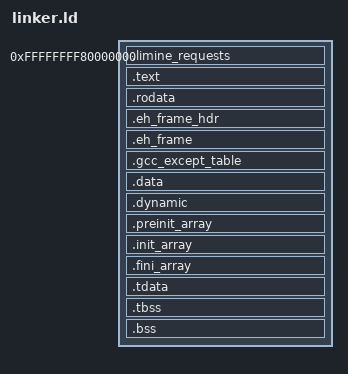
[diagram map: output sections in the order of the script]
/* Tell the linker that we want an x86_64 ELF64 output file */
OUTPUT_FORMAT(elf64-x86-64)

/* We want the symbol _start to be our entry point */
ENTRY(_start)

/* Define the program headers we want so the bootloader gives us the right */
/* MMU permissions; this also allows us to exert more control over the linking */
/* process. */
PHDRS
{
    limine_requests PT_LOAD;
    text PT_LOAD;
    rodata PT_LOAD;
    data PT_LOAD;
    tls PT_TLS;
    dynamic PT_DYNAMIC;
    eh_frame PT_GNU_EH_FRAME;
}

SECTIONS
{
    /* We want to be placed in the topmost 2GiB of the address space, for optimisations */
    /* and because that is what the Limine spec mandates. */
    /* Any address in this region will do, but often 0xffffffff80000000 is chosen as */
    /* that is the beginning of the region. */
    . = 0xffffffff80000000;
    PROVIDE(__ehdr_start = .);

    /* Define a section to contain the Limine requests and assign it to its own PHDR */
    .limine_requests : {
        KEEP(*(.limine_requests_start))
        KEEP(*(.limine_requests))
        KEEP(*(.limine_requests_end))
    } :limine_requests

    /* Move to the next memory page for .text */
    . = ALIGN(CONSTANT(MAXPAGESIZE));

    .text : {
        *(.text .text.*)
    } :text

    /* Move to the next memory page for .rodata */
    . = ALIGN(CONSTANT(MAXPAGESIZE));

    .rodata : {
        *(.rodata .rodata.*)
    } :rodata

    .eh_frame_hdr : {
        KEEP(*(.eh_frame_hdr))
    } :rodata :eh_frame

    .eh_frame : {
        KEEP(*(.eh_frame))
    } :rodata

    .gcc_except_table : {
        KEEP(*(.gcc_except_table))
        KEEP(*(.gcc_except_table.*))
    } :rodata

    /* Move to the next memory page for .data */
    . = ALIGN(CONSTANT(MAXPAGESIZE));

    .data : {
        *(.data .data.*)
    } :data

    /* Dynamic section for relocations, both in its own PHDR and inside data PHDR */
    .dynamic : {
        *(.dynamic)
    } :data :dynamic

    .preinit_array : {
        PROVIDE_HIDDEN(__preinit_array_start = .);
        KEEP(*(.preinit_array .preinit_array.*))
        PROVIDE_HIDDEN(__preinit_array_end = .);
    } :data

    .init_array : {
        PROVIDE_HIDDEN(__init_array_start = .);
        KEEP(*(.init_array .init_array.*))
        PROVIDE_HIDDEN(__init_array_end = .);
    } :data

    .fini_array : {
        PROVIDE_HIDDEN(__fini_array_start = .);
        KEEP(*(.fini_array .fini_array.*))
        PROVIDE_HIDDEN(__fini_array_end = .);
    } :data

    .tdata : {
        *(.tdata .tdata.*)
    } :data :tls

    .tbss : {
        *(.tbss .tbss.*)
        *(.tcommon)
    } :data :tls

    /* NOTE: .bss needs to be the last thing mapped to :data, otherwise lots of */
    /* unnecessary zeros will be written to the binary. */
    /* If you need, for example, .init_array and .fini_array, those should be placed */
    /* above this. */
    .bss : {
        *(.bss .bss.*)
        *(COMMON)
    } :data

    /* Discard .note.* and .eh_frame* since they may cause issues on some hosts. */
    /DISCARD/ : {
        *(.note .note.*)
    }
}
